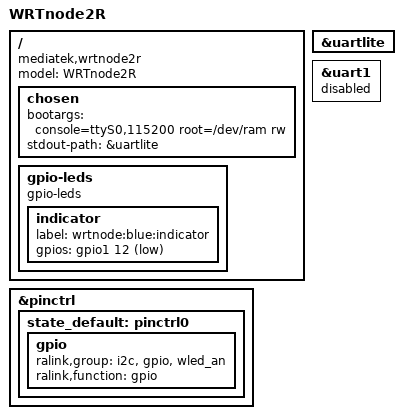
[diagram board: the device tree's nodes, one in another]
/dts-v1/;

#include "WRTNODE2.dtsi"

/ {
	compatible = "mediatek,wrtnode2r", "mediatek,mt7628an-soc";
	model = "WRTnode2R";

	chosen {
		bootargs = "console=ttyS0,115200 root=/dev/ram rw";
		stdout-path = &uartlite;
	};

	gpio-leds {
		compatible = "gpio-leds";

		indicator {
			label = "wrtnode:blue:indicator";
			gpios = <&gpio1 12 1>;
		};
	}; 
};

&pinctrl {
	state_default: pinctrl0 {
		gpio {
			ralink,group = "i2c", "gpio", "wled_an";
			ralink,function = "gpio";
		};
	};
};

&uartlite {
	status = "okay";
};

&uart1 {
	status = "disabled";
};
